# ASR6601 register map
Vendor: ASR Microelectronics; Series: ASR6601; File version: 1
ASR6601 reference description for radio MCU with ARM 32-bit Cortex-M4 Microcontroller
CPU: CM4 r0p1, little endian, no MPU, FPU, 3 interrupt priority bits
Registers are 32-bit, read-write, reset 0x0 unless marked. A register's access mark holds for its fields unless they carry their own. Offsets are from the block's base; lines under a group give offsets from that group; [hi:lo] are bit positions; {n}, {i} and the like mark numbered series; 'fields as' and 'values as' point back to an identical list; <NAME> marks a mode.

## Memory map
0x40000000 RCC size 0x1000 — Reset and clock control
0x40001000 SYSCFG size 0x1000 — System Configuration Controller
0x40003000 UART0 size 0x1000 — Universal Asynchronous Receiver/Transmitter Controller
0x40004000 UART1 size 0x1000
0x40006000 SSP0 size 0x1000 — Synchronous Serial Port Controller
0x40008000 AFEC size 0x1000 — Analog Front-End Controller
0x40009000 LORAC size 0x1000 — LORA Controller
0x40010000 UART2 size 0x1000
0x40011000 UART3 size 0x1000
0x40012000 SSP1 size 0x1000
0x40013000 SSP2 size 0x1000
0x4001F000 GPIOA size 0x400 — General-purpose I/Os
0x4001F400 GPIOB size 0x400
0x4001F800 GPIOC size 0x400
0x4001FC00 GPIOD size 0x400
0x40020000 EFC size 0x1000 — Embedded Flash Controller

## AFEC — Analog Front-End Controller
Base 0x40008000
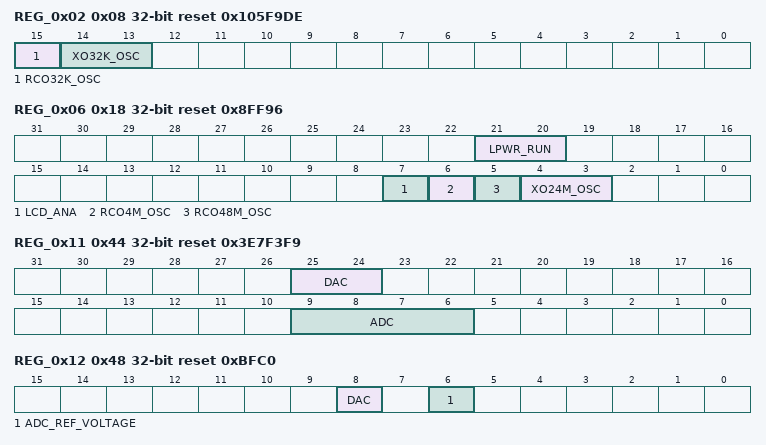
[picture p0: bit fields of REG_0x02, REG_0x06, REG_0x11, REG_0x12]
0x08 REG_0x02 reset 0x105F9DE
  [15] RCO32K_OSC
    0=EN (Enable); 1=DIS (Disable)
  [14:13] XO32K_OSC
    0=EN (Enable); 3=DIS (Disable)
0x0C REG_0x03
  [7] LPWR_XO32K — XO32K low power mode enable
    1=EN (Enable); 0=DIS (Disable)
0x14 REG_0x05
  [3] LPWR_RUN
    0=EN (Enable); 1=DIS (Disable)
0x18 REG_0x06 reset 0x8FF96
  [21:20] LPWR_RUN
    3=EN (Enable); 0=DIS (Disable)
  [7] LCD_ANA
    0=EN (Enable); 1=DIS (Disable)
  [6] RCO4M_OSC
    0=EN (Enable); 1=DIS (Disable)
  [5] RCO48M_OSC
    0=EN (Enable); 1=DIS (Disable)
  [4:3] XO24M_OSC
    1=EN (Enable); 2=DIS (Disable)
0x24 REG_0x09 — LCD register
0x28 REG_0x0A — LCD register
0x2C REG_0x0B — LCD register
0x30 REG_0x0C
0x44 REG_0x11 reset 0x3E7F3F9
  [25:24] DAC
    0=EN (Enable); 3=DIS (Disable)
  [9:6] ADC
    0=EN (Enable); 15=DIS (Disable)
0x48 REG_0x12 reset 0xBFC0
  [8] DAC
    0=EN (Enable); 1=DIS (Disable)
  [6] ADC_REF_VOLTAGE — ADC reference voltage source
    0=EXT (ADC external reference voltage); 1=INT (ADC internal reference voltage)
0x9C REG_0x27
  [12:11] DAC_EN
    1=EN (Enable); 0=DIS (Disable)
0xB0 REG_0x2C
  [25] ADC_VBAT31 — VBAT31 (VBAT/3) voltage
    1=EN (Enable); 0=DIS (Disable)
0x200 CR — Control register
0x204 INT_SR — Interrupt status register
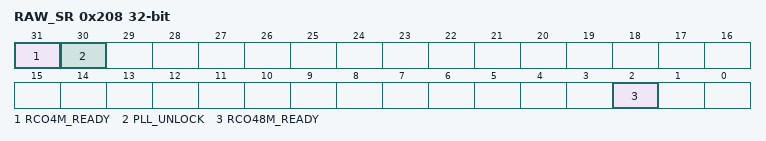
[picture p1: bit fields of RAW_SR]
0x208 RAW_SR ro — Raw status register
  [all] fields
    0=CLR_FLAG (Not ready); 1=SET_FLAG (Ready)
  [31] RCO4M_READY
  [30] PLL_UNLOCK
  [2] RCO48M_READY

## SYSCFG — System Configuration Controller
Base 0x40001000
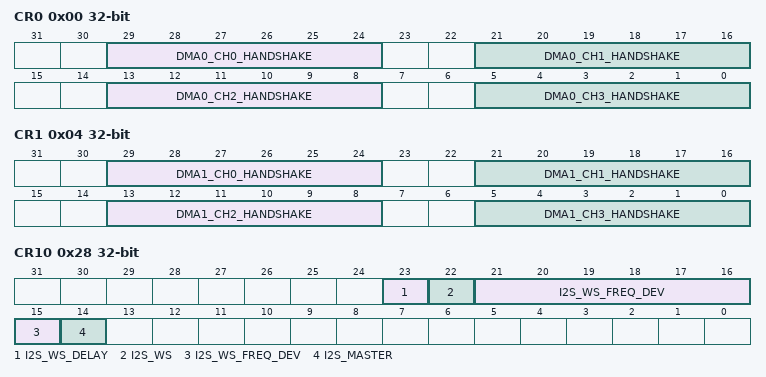
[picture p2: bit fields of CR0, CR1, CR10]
0x00 CR0 — Control register 0
  [all] fields
    4=LORAC_TX; 5=LORAC_RX; 6=DAC_CTRL; 7=ADC_CTRL; 9=SCC; 10=I2C2_TX; 11=I2C2_RX; 12=I2C1_TX; 13=I2C1_RX; 14=I2C0_TX; 15=I2C0_RX; 16=SSP2_TX; 17=SSP2_RX; 18=SSP1_TX; 19=SSP1_RX; 20=SSP0_TX; 21=SSP0_RX; 22=LPUART_TX; 23=LPUART_RX; 24=UART3_TX; 25=UART3_RX; 26=UART2_TX; 27=UART2_RX; 28=UART1_TX; 29=UART1_RX; 30=UART0_TX; 31=UART0_RX; 32=TIMER0_CH3; 33=TIMER0_CH2; 34=TIMER0_CH1; 35=TIMER0_CH0; 36=TIMER0_TRG; 37=TIMER0_UP; 38=TIMER1_CH3; 39=TIMER1_CH2; 40=TIMER1_CH1; 41=TIMER1_CH0; 42=TIMER1_TRG; 43=TIMER1_UP; 44=TIMER2_CH1; 45=TIMER2_CH0; 46=TIMER2_TRG; 47=TIMER2_UP; 48=TIMER3_CH1; 49=TIMER3_CH0; 50=TIMER3_TRG; 51=TIMER3_UP; 52=BSTIMER1_UP; 53=BSTIMER0_UP
  [29-8n:24-8n] DMA0_CH{n}_HANDSHAKE (n=0..3) — DMA0 Channel {n} handshake selection
0x04 CR1 — Control register 1
  [all] fields
    values as the fields of CR0
  [29-8n:24-8n] DMA1_CH{n}_HANDSHAKE (n=0..3) — DMA1 Channel {n} handshake selection
0x08 CR2 — Control register 2
0x0C CR3 — Control register 3
0x10 CR4 — Control register 4
  [29] BOOT_MODE
    0=APP (Application); 1=BTL (Bootloader)
{0x0+4i} CR{i} (i=5..9) — Control register {i}
0x28 CR10 — Control register 10
  [23] I2S_WS_DELAY
  [22] I2S_WS — I2S WS output
    1=EN (Enable); 0=DIS (Disable)
  [21:15] I2S_WS_FREQ_DEV — I2S WS frequency divider
  [14] I2S_MASTER — I2S master mode
    1=EN (Enable); 0=DIS (Disable)

## Licence text in the file
Copyright (c) 2022 Vladimir Alemasov. All rights reserved . This program and the accompanying materials are distributed under the terms of GNU General Public License version 2 as published by the Free Software Foundation. . This program is distributed in the hope that it will be useful, but WITHOUT ANY WARRANTY; without even the implied warranty of. MERCHANTABILITY or FITNESS FOR A PARTICULAR PURPOSE. See the. GNU General Public License for more details.
